# SAMA7G54D1GN2 register map
Vendor: Microchip Technology; Series: SAMA7G5; File version: 0
Registers are 32-bit, read-write, reset 0x0 unless marked. A register's access mark holds for its fields unless they carry their own. Offsets are from the block's base; [hi:lo] are bit positions; {n}, {i} and the like mark numbered series.

## PDMC0 — Pulse Density Microphone Controller
Base 0xE1608000; register names take the prefix PDMC_
Same registers: PDMC1 0xE160C000
0x00 CR wo — Control Register
  [0] SWRST — Software Reset
    0=No effect; 1=Resets the PDMC interface
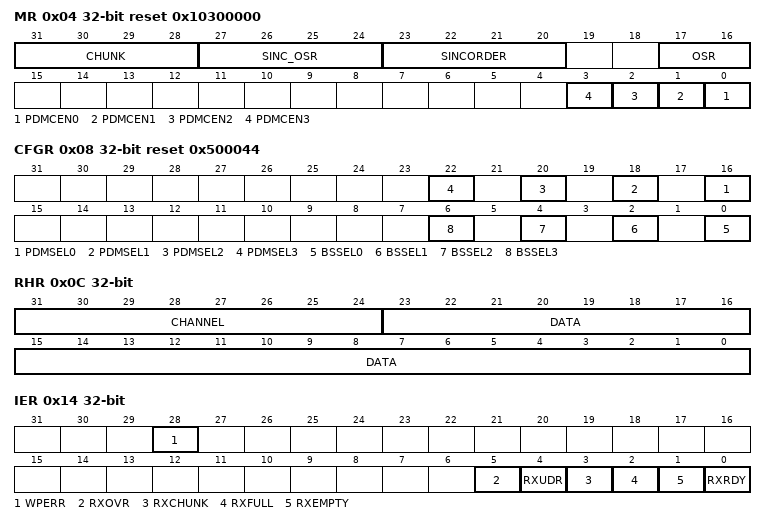
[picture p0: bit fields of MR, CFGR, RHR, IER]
0x04 MR reset 0x10300000 — Mode Register
  [31:28] CHUNK — Chunk Size
  [27:24] SINC_OSR — SINC Filter Oversampling Ratio
    0=DISABLE (Audio filtering mode. The SINC filter OSR is implicitly defined by the PDMC_MR.OSR field.); 1=OSR8 (The SINC filter OSR is 8.); 2=OSR16 (The SINC filter OSR is 16.); 3=OSR32 (The SINC filter OSR is 32.); 4=OSR64 (The SINC filter OSR is 64.); 5=OSR128 (The SINC filter OSR is 128.); 6=OSR256 (The SINC filter OSR is 256.)
  [23:20] SINCORDER — SINC Filter Order
    1=ORDER1 (SINC filter order is 1.); 2=ORDER2 (SINC filter order is 2.); 3=ORDER3 (SINC filter order is 3. Recommended if SINC_OSR=0); 4=ORDER4 (SINC filter order is 4.); 5=ORDER5 (SINC filter order is 5.)
  [17:16] OSR — Audio Oversampling Ratio
    1=OSR is 64; 2=OSR is 128; 3=OSR is 256
  [n] PDMCEN{n} (n=0..3) — PDMC Channel {n} Enable
    0=DISABLE (PDMC is disabled.); 1=ENABLE (PDMC is enabled.)
0x08 CFGR reset 0x500044 — Configuration Register
  [2n+16] PDMSEL{n} (n=0..3) — PDM Microphone Source Selection
    0=DS0 (PDMSELx corresponds to PMDC_DS0.); 1=DS1 (PDMSELx corresponds to PMDC_DS1.)
  [2n] BSSEL{n} (n=0..3) — Bitstream Source Selection
    0=The selected PDMC_DSx source is sampled on the positive edge of PDMC_CLK; 1=The selected PDMC_DSx source is sampled on the negative edge of PDMC_CLK
0x0C RHR ro — Receive Holding Register
  [31:24] CHANNEL — Channel Index of Data
  [23:0] DATA — Converted Data
0x14 IER wo — Interrupt Enable Register
  [28] WPERR — Write Protect Event Interrupt Enable
  [5] RXOVR — Receive Over Flow Interrupt Enable
  [4] RXUDR — Receive Under Flow Interrupt Enable
  [3] RXCHUNK — Receive FIFO Chunk Interrupt Enable
  [2] RXFULL — Receive FIFO Full Interrupt Enable
  [1] RXEMPTY — Receive FIFO Empty Interrupt Enable
  [0] RXRDY — Receive Ready Interrupt Enable
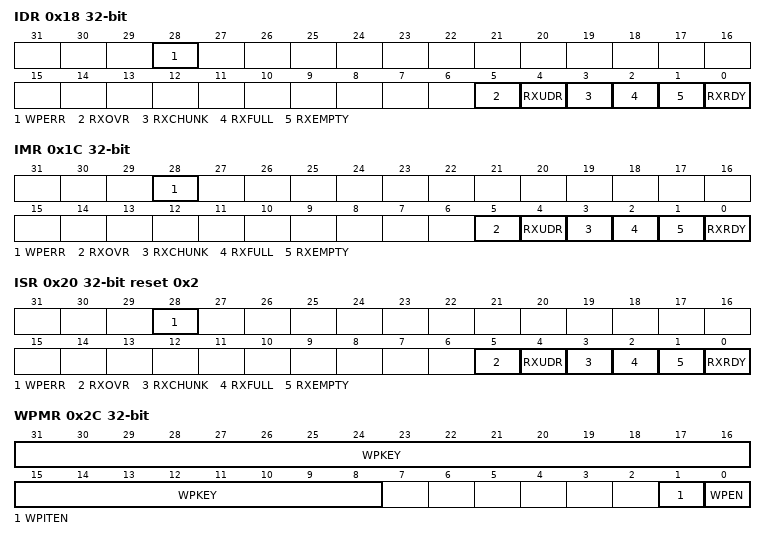
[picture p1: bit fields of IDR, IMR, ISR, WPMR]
0x18 IDR wo — Interrupt Disable Register
  [28] WPERR — Write Protect Event Interrupt Disable
  [5] RXOVR — Receive Over Flow Interrupt Disable
  [4] RXUDR — Receive Under Flow Interrupt Disable
  [3] RXCHUNK — Receive FIFO Chunk Interrupt Disable
  [2] RXFULL — Receive FIFO Full Interrupt Disable
  [1] RXEMPTY — Receive FIFO Empty Interrupt Disable
  [0] RXRDY — Receive Ready Interrupt Disable
0x1C IMR ro — Interrupt Mask Register
  [28] WPERR — Write Protect Event Interrupt Mask
  [5] RXOVR — Receive Over Flow Interrupt Mask
  [4] RXUDR — Receive Under Flow Interrupt Mask
  [3] RXCHUNK — Receive FIFO Chunk Interrupt Mask
  [2] RXFULL — Receive FIFO Full Interrupt Mask
  [1] RXEMPTY — Receive FIFO Empty Interrupt Mask
  [0] RXRDY — Receive Ready Interrupt Mask
0x20 ISR ro reset 0x2 — Interrupt Status Register
  [28] WPERR — Write Protect Event Interrupt Status (cleared on read)
    0=No security event has occurred since the last read of PDMC_ISR; 1=One or more security events occurred since the last read of PDMC_ISR. For details on the event(s), see PDMC Write Protection Status Register.
  [5] RXOVR — Receive Over Flow Interrupt Status (cleared on read)
    0=No overflow event occurred since the last read of PDMC_ISR; 1=At least one overflow event occurred since the last read of PDMC_ISR
  [4] RXUDR — Receive Under Flow Interrupt Status (cleared on read)
    0=No underflow event occurred since the last read of PDMC_ISR; 1=At least one underflow event occurred since the last read of PDMC_ISR
  [3] RXCHUNK — Receive FIFO Chunk Interrupt Status (cleared by reading PDMC_RHR)
    0=There is less than PDMC_MR.CHUNK data in the RX FIFO; 1=At least PDMC_MR.CHUNK data can be read in the RX FIFO
  [2] RXFULL — Receive FIFO Full Interrupt Status (cleared by reading PDMC_RHR)
    0=The RX FIFO is not full and can still receive data; 1=The RX FIFO is full and cannot receive more data
  [1] RXEMPTY — Receive FIFO Empty Interrupt Status (automatically cleared when an audio sample is generated)
    0=At least one data is in the RX FIFO; 1=The RX FIFO is empty
  [0] RXRDY — Receive Ready Interrupt Status (cleared by reading PDMC_RHR)
    0=There is no data in the RX FIFO; 1=At least one data is in the RX FIFO and can be read through PDMC_RHR
0x2C WPMR — Write Protection Mode Register
  [31:8] WPKEY — Write Protection Key
    0x50444D=PASSWD (Writing any other value in this field aborts the write operation of the WPEN and WPITEN bits. Always read at 0.)
  [1] WPITEN — Write Protection Enable for Interrupt
    0=Disables the write protection on interrupt registers if WPKEY corresponds to 0x50444D ('PDM' in ASCII); 1=Enables the write protection on interrupt registers if WPKEY corresponds to 0x50444D ('PDM' in ASCII)
  [0] WPEN — Write Protection Enable for Configuration Registers
    0=Disables write protection if WPKEY corresponds to 0x50444D ('PDM' in ASCII); 1=Enables write protection if WPKEY corresponds to 0x50444D ('PDM' in ASCII)
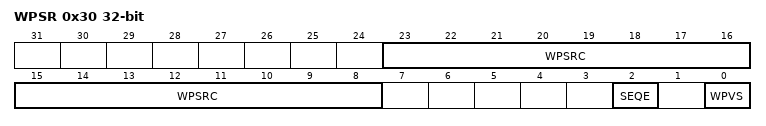
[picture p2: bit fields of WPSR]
0x30 WPSR ro — Write Protection Status Register
  [23:8] WPSRC — Write Protection Source
  [2] SEQE — Internal Sequencer Error (cleared on read)
    0=No peripheral internal sequencer error has occurred since the last read of PDMC_WPSR; 1=A peripheral internal sequencer error has occurred since the last read of PDMC_WPSR
  [0] WPVS — Write Protection Violation Status (cleared on read)
    0=No write protection violation has occurred since the last read of PDMC_WPSR; 1=A write protection violation has occurred since the last read of PDMC_WPSR. If this violation is an unauthorized attempt to write a protected register, the associated violation is reported into the field WPSRC.
